# SC32F10T_10G register map
File version: 1.0
CPU: CM0+ r0p1, little endian, MPU, no FPU, 4 interrupt priority bits
Registers are 32-bit, read-write, reset 0x0 unless marked. A register's access mark holds for its fields unless they carry their own. Offsets are from the block's base; [hi:lo] are bit positions; 'fields as' and 'values as' point back to an identical list.

## DMA1
Base 0x40010840
0x00 DMA1_SADR — DMA 源地址缓存寄存器
  [31:0] SADR — DMA传输源地址缓存读取：当通道打开时，读到的是内部的源地址工作寄存器；当通道禁止时，读到的是表面上的源地址缓存寄存器。更新：每搬运完一次，源地址工作寄存器会根据SAINC[1:0]设置自动变化，其变化的宽度根据TXWIDTH[1:0]决定。循环模式下(SAINC == 11)，源地址缓存寄存器会重载至源地址工作寄存器。写入：写源地址缓存寄存器的条件：CHEN=0，或CHEN=1，但DMA通道已传
0x00 DMA0_SADR — DMA 源地址缓存寄存器
  fields as DMA1_SADR
0x04 DMA1_DADR — DMA 目标地址缓存寄存器
  [31:0] DADR — DMA传输目标地址缓存读取：当通道打开时，读到的是内部的目标地址工作寄存器；当通道禁止时，读到的是表面上的目标地址缓存寄存器。更新：每搬运完一次，目标地址工作寄存器会根据DAINC[1:0]设置自动变化，其变化的宽度根据TXWIDTH[1:0]决定。循环模式下(SAINC == 11)，目标地址缓存寄存器会重载至目标地址工作寄存器。写入：写目标地址缓存寄存器的条件：CHEN=0，或CHEN=1，但
0x04 DMA0_DADR — DMA 目标地址缓存寄存器
  fields as DMA1_DADR
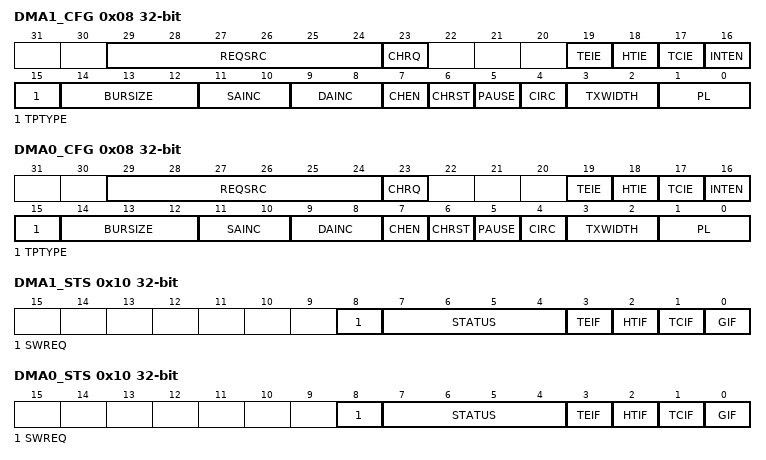
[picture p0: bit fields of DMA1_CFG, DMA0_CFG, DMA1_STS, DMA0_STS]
0x08 DMA1_CFG — DMA 控制/配置寄存器
  [29:24] REQSRC — DMA通道请求源选择位0：禁用当前DMA通道的外设请求选择以下配置值，当前DMA通道的外设请求源将配合设置项中的外设DMA请求使能开关产生：2：UART0_IDE->TXDMAEN3：UART0_IDE->RXDMAEN4：UART1_IDE->TXDMAEN5：UART1_IDE->RXDMAEN12：SPI0_IDE->TXDMAEN13：SPI0_IDE->RXDMAEN14：SPI1_ID
  [23] CHRQ — DMA通道的DMA请求使能位0：禁止，当前DMA通道禁止作为其它DMA通道的请求源1：使能，当前DMA通道可作为其它DMA通道的请求源，即当前DMA通道和其它外设一样，可产生DMA请求。该位使能后，可以实现DMA请求DMA，例如：CHRQ =1，DMA通道n完成数据搬运后，向DMA通道m产生一个DMA请求，通道m响应请求，将预先配置好的参数表更新至通道n的寄存器，从而实现通道n的参数自动更新。
  [19] TEIE — DMA 传输错误中断使能位0：DMA 传输错误中断除能1：DMA 传输错误中断使能
  [18] HTIE — DMA 传输一半中断使能位0：DMA 传输一半中断除能1：DMA 传输一半中断使能
  [17] TCIE — DMA 传输完成中断使能位0：DMA 传输完成中断除能1：DMA 传输完成中断使能
  [16] INTEN — 中断请求 CPU的使能控制位0：禁止中断请求1：使能中断请求
  [15] TPTYPE — DMA通道传输类型选择位0：单次传输1：批量传输。批量传输模式下，DMA控制器搬移DMACNT个数据仅需一次请求，通道响应该请求后，数据将以Burst方式进行传输，即以BURSIZE为单位进行数据搬运直到DMACNT递减为0，一次批量传输模式下的数据处理才算完成。
  [14:12] BURSIZE — 批量传输时，基于 Burst 传输方式下的定义，Burst 大小可选择：000：128001：64010：32011：16100：8101：4110：2111：1
  [11:10] SAINC — DMA通道传输源地址增减模式设置位00: 无增量(固定地址模式)01: 增量模式10: 减量模式11: 递增循环模式 (见DMA传输源地址缓存寄存器)SAINC[1:0]的值可以任意修改，在通道禁止时立即生效；在通道使能时，修改值在循环模式重装载时生效
  [9:8] DAINC — DMA 传输目标地址增减模式设置位00: 无增量(固定地址模式)01: 增量模式10: 减量模式11: 递增循环模式 (见DMA传输目标地址缓存寄存器)DAINC[1:0]的值可以任意修改，在通道禁止时立即生效；在通道使能时，修改值在循环模式重装载时生效
  [7] CHEN — DMA通道使能位0： DMA通道禁止1： DMA通道使能
  [6] CHRST — DMA通道复位控制位，该位用于控制DMA通道复位。0：无效1：当前DMA通道复位。此时，当前DMA通道的CHEN被除能，中断标志为被清除，其他寄存器的值保持不变
  [5] PAUSE — DMA通道传输暂停控制位0：无效1：当前DMA通道暂停。此时，当前DMA通道的CHEN被除能，状态机在完成当前读写周期后回到 state=1，内部寄存器的值处于保持状态(源/目的地址，计数器)，当再次使能当前DMA通道的CHEN时，当前DMA通道的会继续上一次的传输；PAUSE会被写CHEN的动作清0
  [4] CIRC — DMA通道循环模式使能位0：通道未处于循环模式，在达到设定的待传输数据数目时，该通道的DMACNT会保持为零；1：通道处于循环模式，在传输完成后该通道的DMACNT会自动重新装载之前设定的值。循环模式可用于处理循环缓冲区和连续数据流（例如ADC扫描模式）。在循环模式传输过程中，待传输数据的数目将自动重新装载为在通道配置阶段设置的初始值，并继续响应 DMA 请求。为停止循环传输，软件需要在禁止 DM
  [3:2] TXWIDTH — DMA通道传输宽度选择位选择当前DMA通道的源地址及目标地址每次传输的数据宽度：00：8bit01：16bit10：32bit11：32bitTXWIDTH[1:0] 的值可以任意修改，在通道禁止时，立即生效；在通道打开时，修改值在循环模式重装载时生效。
  [1:0] PL — DMA通道优先级设置位 在 DMA 已经有通道在工作，且其它通道也接收到请求正挂起，当正在工作的通道结束后将启动优先级仲裁。00：低01：中10：高11：非常高注意：同等优先级配置，通道号越小优先级越高。
0x08 DMA0_CFG — DMA 控制/配置寄存器
  fields as DMA1_CFG
0x0C DMA1_CNT — DMA 计数器缓存寄存器
  [31:0] DMACNT — DMA通道计数器缓存寄存器写入：DMACNT的值等于当前DMA通道的剩余传输次数；每个DMA通道内部都有一个“工作计数器”，该计数器会在每次搬运后以为TXWIDTH 为单位递减：当CIRC=0（DMA通道处于非循环模式）时，“工作计数器”递减到0后，将不再接受任何 DMA 请求。当CIRC=1（DMA通道处于循环模式）时，“工作计数器”递减到0后，会将DMACNT的值重载到“工作计数器”内，等待下
0x0C DMA0_CNT — DMA 计数器缓存寄存器
  fields as DMA1_CNT
0x10 DMA1_STS — DMA 状态寄存器
  [8] SWREQ — DMA通道的软件请求触发位该位写1后，当前DMA通道会一直挂起软件请求，直到当前DMA通道响应，并将该位自动硬件清0。
  [7:4] STATUS — DMA通道状态位0000：空闲。0001：写入源地址0010：读取源地址数据，并写入目的地址0011：写入目的地址数据0100：保留0101：挂起等待中(有通道在忙，其他通道请求挂起)0110：暂停等待中(批量传输模式时PAUSE写1后)0111：burst传输中1000：burst传输停止：PAUSE使能、DMACNT计数到0，或bursize计数到0均会进入此状态
  [3] TEIF — DMA 传输错误中断标志位当DMA读写到未定义的地址时，TEIF会被硬件置1。该位写1清零。
  [2] HTIF — DMA 传输一半中断标志位当DMACNT的计数值计数到DMACNT/2时，HTIF会被硬件置1。该位写1清零。
  [1] TCIF — DMA 传输完成中断标志位当DMACNT的计数值计到0时，TCIF会被硬件置1。该位写1清零。
  [0] GIF — DMA通道全局中断标志位0：当前DMA通道无中断产生1：当前DMA通道产生中断：传输错误、传输到一半或传输完成
0x10 DMA0_STS — DMA 状态寄存器
  fields as DMA1_STS

## DMA2
Base 0x40010880
Registers as DMA1 (with DMA1 read as DMA2).

## DMA3
Base 0x400108C0
Registers as DMA1 (with DMA1 read as DMA3).
